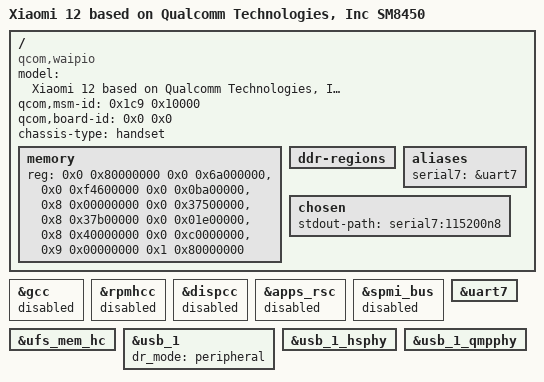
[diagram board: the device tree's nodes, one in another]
// SPDX-License-Identifier: BSD-3-Clause
/*
 * cupid QUARANTINE-B: only the clock / PMIC-bus group disabled.
 * Peripheral group (UFS, USB, PCIe, SDHCI, UART) enabled.
 */

/dts-v1/;

#include "sm8450.dtsi"
#include "pm8350.dtsi"
#include "pm8350b.dtsi"
#include "pm8350c.dtsi"
#include "pm8450.dtsi"
#include "pmk8350.dtsi"
#include "pmr735a.dtsi"
#include "sm8450-xiaomi-cupid-syms.dtsi"

/ {
	model = "Xiaomi 12 based on Qualcomm Technologies, Inc SM8450";
	compatible = "qcom,waipio", "xiaomi,cupid", "qcom,sm8450";
	qcom,msm-id = <0x1c9 0x10000>;
	qcom,board-id = <0x0 0x0>;
	chassis-type = "handset";

	memory {
		device_type = "memory";
		reg = <0x0 0x80000000 0x0 0x6a000000>,
		      <0x0 0xf4600000 0x0 0x0ba00000>,
		      <0x8 0x00000000 0x0 0x37500000>,
		      <0x8 0x37b00000 0x0 0x01e00000>,
		      <0x8 0x40000000 0x0 0xc0000000>,
		      <0x9 0x00000000 0x1 0x80000000>;
	};

	ddr-regions {
	};

	aliases {
		serial7 = &uart7;
	};

	chosen {
		stdout-path = "serial7:115200n8";
	};
};

/ { /delete-node/ memory@a0000000; };

&gcc		{ status = "disabled"; };
&rpmhcc		{ status = "disabled"; };
&dispcc		{ status = "disabled"; };
&apps_rsc	{ status = "disabled"; };
&spmi_bus	{ status = "disabled"; };

/* 外设组打开 */
&uart7		{ status = "okay"; };
&ufs_mem_hc	{ status = "okay"; };
&usb_1		{ status = "okay"; dr_mode = "peripheral"; };
&usb_1_hsphy	{ status = "okay"; };
&usb_1_qmpphy	{ status = "okay"; };
